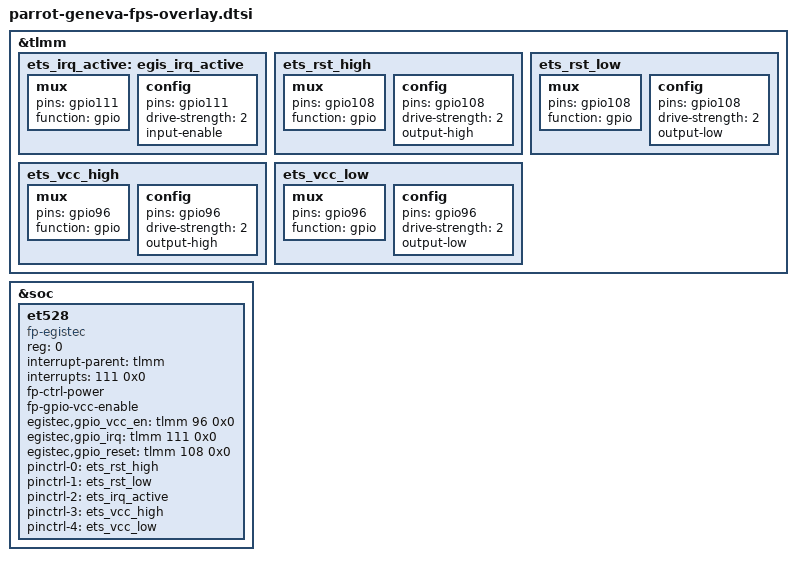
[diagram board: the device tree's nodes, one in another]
&tlmm {
	ets_irq_active: egis_irq_active {
		/* INTERRUPT */
		mux {
			pins = "gpio111";
			function = "gpio";
		};

		config {
			pins = "gpio111";
			drive-strength = <2>; /* 2 MA */
			input-enable;
		};
	};

	ets_rst_high: ets_rst_high {
		/* INTERRUPT */
		mux {
			pins = "gpio108";
			function = "gpio";
		};

		config {
			pins = "gpio108";
			drive-strength = <2>; /* 2 MA */
			output-high;
		};
	};

	ets_rst_low: ets_rst_low {
		/* INTERRUPT */
		mux {
			pins = "gpio108";
			function = "gpio";
		};

		config {
			pins = "gpio108";
			drive-strength = <2>; /* 2 MA */
			output-low;
		};
	};

	ets_vcc_high: ets_vcc_high {
		/* INTERRUPT */
		mux {
			pins = "gpio96";
			function = "gpio";
		};

		config {
			pins = "gpio96";
			drive-strength = <2>; /* 2 MA */
			output-high;
		};
	};

	ets_vcc_low: ets_vcc_low {
		/* INTERRUPT */
		mux {
			pins = "gpio96";
			function = "gpio";
		};

		config {
			pins = "gpio96";
			drive-strength = <2>; /* 2 MA */
			output-low;
		};
	};
};

&soc {
	et528: et528 {
		compatible = "fp-egistec";
		status = "ok";
		reg = <0>;
		interrupt-parent = <&tlmm>;
		interrupts = <111 0x0>;
		fp-ctrl-power;
		fp-gpio-vcc-enable;
		egistec,gpio_vcc_en = <&tlmm 96 0x0>;
		egistec,gpio_irq = <&tlmm 111 0x0>;
		egistec,gpio_reset = <&tlmm 108 0x0>;
		pinctrl-names = "egis_rst_high", "egis_rst_low", "egis_irq_active",
				"egis_vcc_high", "egis_vcc_low";
		pinctrl-0 = <&ets_rst_high>;
		pinctrl-1 = <&ets_rst_low>;
		pinctrl-2 = <&ets_irq_active>;
		pinctrl-3 = <&ets_vcc_high>;
		pinctrl-4 = <&ets_vcc_low>;
	};

};
